# GD32G5x3 register map
File version: 1.0
CPU: CM33 r2p1, little endian, MPU, FPU, 4 interrupt priority bits
Registers are 32-bit, read-write, reset 0x0 unless marked. A register's access mark holds for its fields unless they carry their own. Offsets are from the block's base; [hi:lo] are bit positions; {n}, {i} and the like mark numbered series.

## HRTIMER_SLAVE_TIMER2
Base 0x40015980
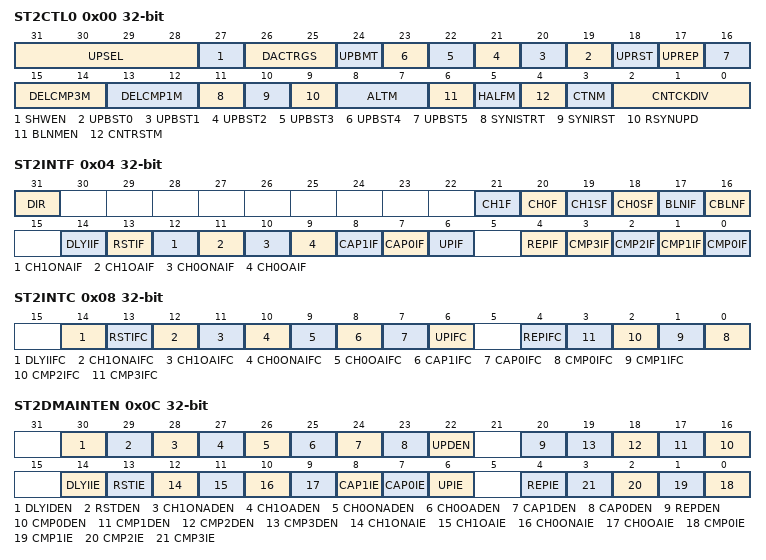
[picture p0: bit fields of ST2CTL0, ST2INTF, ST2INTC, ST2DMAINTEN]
0x00 ST2CTL0 — HRTIMER Slave_TIMER2 control register 0
  [31:28] UPSEL — Update event selection
  [27] SHWEN — Shadow registers enable
  [26:25] DACTRGS — Trigger source to DAC
  [24] UPBMT — Update by Master_TIMER update event
  [n+19] UPBST{n} (n=0..4) — Update by Slave_TIMER{n} update event
  [18] UPRST — Update event generated by reset event
  [17] UPREP — Update event generated by repetition event
  [16] UPBST5 — Update by Slave_TIMER5 update event
  [15:14] DELCMP3M — Compare 3 delayed mode
  [13:12] DELCMP1M — Compare 1 delayed mode
  [11] SYNISTRT — Synchronous input start timer
  [10] SYNIRST — Synchronous input reset timer
  [9] RSYNUPD — Re-synchronized update
  [8:7] ALTM — Alternate mode
  [6] BLNMEN — Balanced mode enable
  [5] HALFM — Half mode
  [4] CNTRSTM — Counter reset mode
  [3] CTNM — Continuous mode
  [2:0] CNTCKDIV — Counter clock division
0x04 ST2INTF ro — HRTIMER Slave_TIMER2 interrupt flag register
  [31] DIR — Direction
  [21] CH1F — Channel 1 output flag
  [20] CH0F — Channel 0 output flag
  [19] CH1SF — Channel 1 output state flag
  [18] CH0SF — Channel 0 output state flag
  [17] BLNIF — Balanced IDLE flag
  [16] CBLNF — Current balanced flag
  [14] DLYIIF — Delayed IDLE mode entry interrupt flag
  [13] RSTIF — Counter reset interrupt flag
  [12] CH1ONAIF — Channel 1 output inactive interrupt flag
  [11] CH1OAIF — Channel 1 output active interrupt flag
  [10] CH0ONAIF — Channel 0 output inactive interrupt flag
  [9] CH0OAIF — Channel 0 output active interrupt flag
  [8] CAP1IF — Capture 1 interrupt flag
  [7] CAP0IF — Capture 0 interrupt flag
  [6] UPIF — Update interrupt flag
  [4] REPIF — Repetition interrupt flag
  [n] CMP{n}IF (n=0..3) — Compare {n} interrupt flag
0x08 ST2INTC wo — HRTIMER Slave_TIMER2 interrupt flag clear register
  [14] DLYIIFC — Clear delayed IDLE mode entry interrupt flag
  [13] RSTIFC — Clear counter reset interrupt flag
  [12] CH1ONAIFC — Clear channel 1 output inactive interrupt flag
  [11] CH1OAIFC — Clear channel 1 output active interrupt flag
  [10] CH0ONAIFC — Clear channel 0 output inactive interrupt flag
  [9] CH0OAIFC — Clear channel 0 output active interrupt flag
  [8] CAP1IFC — Clear capture 1 interrupt flag
  [7] CAP0IFC — Clear capture 0 interrupt flag
  [6] UPIFC — Clear update interrupt flag
  [4] REPIFC — Clear repetition interrupt flag
  [n] CMP{n}IFC (n=0..3) — Clear compare {n} interrupt flag
0x0C ST2DMAINTEN — HRTIMER Slave_TIMER2 DMA and interrupt enable register
  [30] DLYIDEN — Delayed IDLE mode entry DMA request enable
  [29] RSTDEN — Counter reset DMA request enable
  [28] CH1ONADEN — Channel 1 output inactive DMA request enable
  [27] CH1OADEN — Channel 1 output active DMA request enable
  [26] CH0ONADEN — Channel 0 output inactive DMA request enable
  [25] CH0OADEN — Channel 0 output active DMA request enable
  [24] CAP1DEN — Capture 1 DMA request enable
  [23] CAP0DEN — Capture 0 DMA request enable
  [22] UPDEN — Update DMA request enable
  [20] REPDEN — Repetition DMA request enable
  [n+16] CMP{n}DEN (n=0..3) — Compare {n} DMA request enable
  [14] DLYIIE — Delayed IDLE mode entry interrupt enable
  [13] RSTIE — Counter reset interrupt enable
  [12] CH1ONAIE — Channel 1 output inactive interrupt enable
  [11] CH1OAIE — Channel 1 output active interrupt enable
  [10] CH0ONAIE — Channel 0 output inactive interrupt enable
  [9] CH0OAIE — Channel 0 output active interrupt enable
  [8] CAP1IE — Capture 1 interrupt enable
  [7] CAP0IE — Capture 0 interrupt enable
  [6] UPIE — Update interrupt enable
  [4] REPIE — Repetition interrupt enable
  [n] CMP{n}IE (n=0..3) — Compare {n} interrupt enable
0x10 ST2CNT — HRTIMER Slave_TIMER2 counter register
  [15:0] CNT — The current counter value
0x14 ST2CAR reset 0xFFDF — HRTIMER Slave_TIMER2 counter auto reload register
  [15:0] CARL — Counter auto reload value
0x18 ST2CREP — HRTIMER Slave_TIMER2 counter repetition register
  [7:0] CREP — Counter repetition value
0x1C ST2CMP0V — HRTIMER Slave_TIMER2 compare 0 value register
  [15:0] CMP0VAL — Compare 0 value
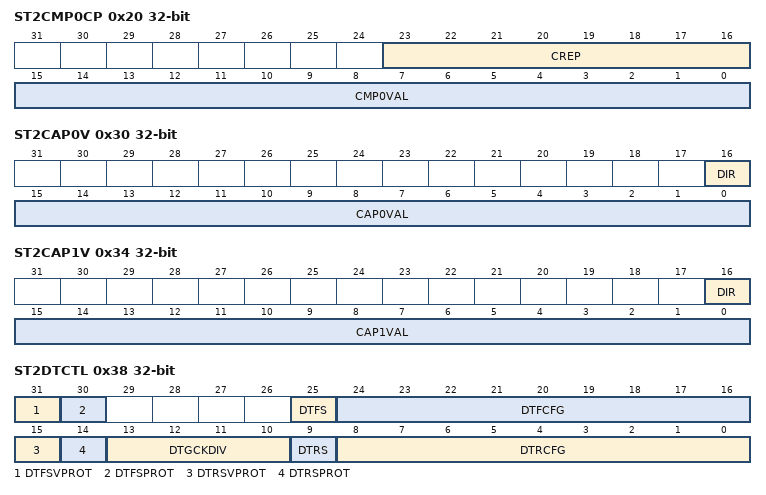
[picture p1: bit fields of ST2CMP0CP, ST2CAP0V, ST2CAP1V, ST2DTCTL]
0x20 ST2CMP0CP — HRTIMER Slave_TIMER2 compare 0 composite register
  [23:16] CREP — Counter repetition value
  [15:0] CMP0VAL — Compare 0 value
{0x20+4i} ST2CMP{i}V (i=1..3) — HRTIMER Slave_TIMER2 compare {i} value register
  [15:0] CMP{i}VAL — Compare {i} value
0x30 ST2CAP0V ro — HRTIMER Slave_TIMER2 capture 0 value register
  [16] DIR — Slave_timer 0 capture 1 direction status
  [15:0] CAP0VAL — Capture 0 value
0x34 ST2CAP1V ro — HRTIMER Slave_TIMER2 capture 1 value register
  [16] DIR — Slave_Timer 0 capture 1 direction status
  [15:0] CAP1VAL — Capture 1 value
0x38 ST2DTCTL — HRTIMER Slave_TIMER2 dead-time control register
  [31] DTFSVPROT — Dead-time falling edge protection for value and sign
  [30] DTFSPROT — Dead-time falling edge protection for sign
  [25] DTFS — The sign of falling edge dead-time value
  [24:16] DTFCFG — Falling edge dead-time value
  [15] DTRSVPROT — Dead-time rising edge protection for value and sign
  [14] DTRSPROT — Dead-time rising edge protection for sign
  [13:10] DTGCKDIV — Dead time clock division
  [9] DTRS — The sign of rising edge dead-time value
  [8:0] DTRCFG — Rising edge dead-time value
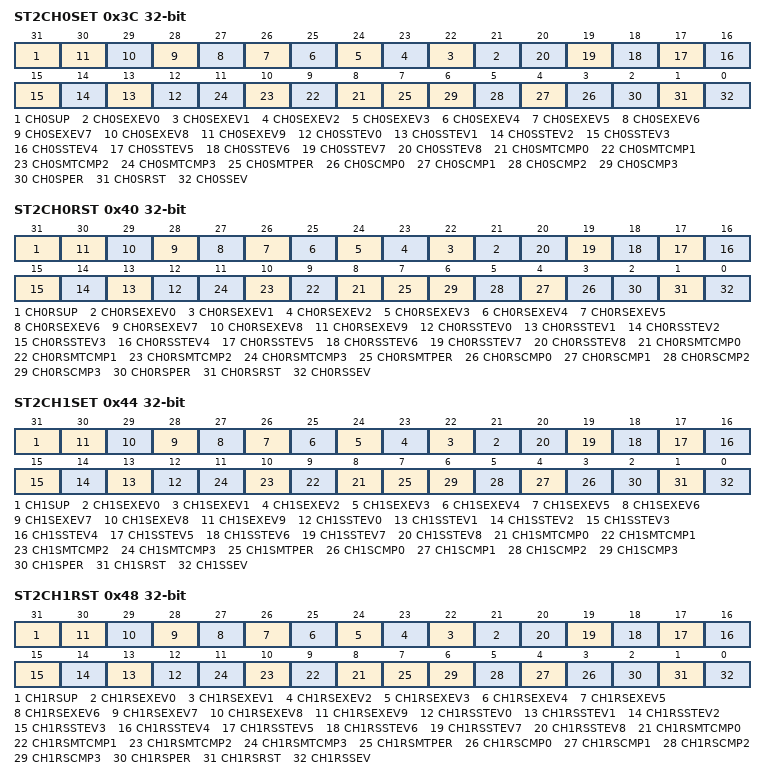
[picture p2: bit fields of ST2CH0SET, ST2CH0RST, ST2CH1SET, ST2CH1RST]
0x3C ST2CH0SET — HRTIMER Slave_TIMER2 channel 0 set request register
  [31] CH0SUP — Update event generates channel 0 set request
  [n+21] CH0SEXEV{n} (n=0..9) — External event {n} generates channel 0 set request
  [n+12] CH0SSTEV{n} (n=0..8) — interconnection event {n} generates channel 0 set request
  [n+8] CH0SMTCMP{n} (n=0..3) — Master_TIMER compare {n} event generates channel 0 set request
  [7] CH0SMTPER — Master_TIMER period event generates channel 0 set request
  [n+3] CH0SCMP{n} (n=0..3) — compare {n} event generates channel 0 set request
  [2] CH0SPER — period event generates channel 0 set request
  [1] CH0SRST — reset event generates channel 0 set request
  [0] CH0SSEV — Software event generates channel 0 set request
0x40 ST2CH0RST — HRTIMER Slave_TIMER2 channel 0 reset request register
  [31] CH0RSUP — Update event generates channel 0 reset request
  [n+21] CH0RSEXEV{n} (n=0..9) — External event {n} generates channel 0 reset request
  [n+12] CH0RSSTEV{n} (n=0..8) — interconnection event {n} generates channel 0 reset request
  [n+8] CH0RSMTCMP{n} (n=0..3) — Master_TIMER compare {n} event generates channel 0 reset request
  [7] CH0RSMTPER — Master_TIMER period event generates channel 0 reset request
  [n+3] CH0RSCMP{n} (n=0..3) — compare {n} event generates channel 0 reset request
  [2] CH0RSPER — period event generates channel 0 reset request
  [1] CH0RSRST — reset event generates channel 0 reset request
  [0] CH0RSSEV — Software event generates channel 0 reset request
0x44 ST2CH1SET — HRTIMER Slave_TIMER2 channel 1 set request register
  [31] CH1SUP — Update event generates channel 1 set request
  [n+21] CH1SEXEV{n} (n=0..9) — External event {n} generates channel 1 set request
  [n+12] CH1SSTEV{n} (n=0..8) — interconnection event {n} generates channel 1 set request
  [n+8] CH1SMTCMP{n} (n=0..3) — Master_TIMER compare {n} event generates channel 1 set request
  [7] CH1SMTPER — Master_TIMER period event generates channel 1 set request
  [n+3] CH1SCMP{n} (n=0..3) — compare {n} event generates channel 1 set request
  [2] CH1SPER — period event generates channel 1 set request
  [1] CH1SRST — reset event generates channel 1 set request
  [0] CH1SSEV — Software event generates channel 1 set request
0x48 ST2CH1RST — HRTIMER Slave_TIMER2 channel 1 reset request register
  [31] CH1RSUP — Update event generates channel 1 reset request
  [n+21] CH1RSEXEV{n} (n=0..9) — External event {n} generates channel 1 reset request
  [n+12] CH1RSSTEV{n} (n=0..8) — interconnection event {n} generates channel 1 reset request
  [n+8] CH1RSMTCMP{n} (n=0..3) — Master_TIMER compare {n} event generates channel 1 reset request
  [7] CH1RSMTPER — Master_TIMER period event generates channel 1 reset request
  [n+3] CH1RSCMP{n} (n=0..3) — compare {n} event generates channel 1 reset request
  [2] CH1RSPER — period event generates channel 1 reset request
  [1] CH1RSRST — reset event generates channel 1 reset request
  [0] CH1RSSEV — Software event generates channel 1 reset request
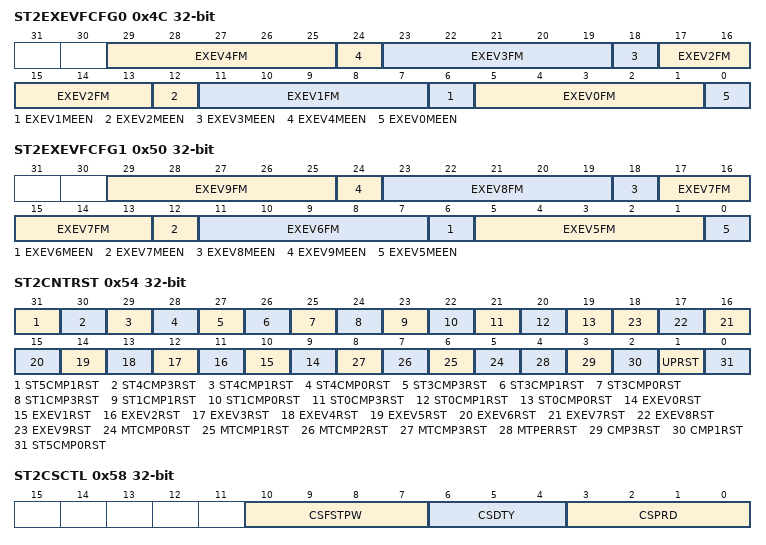
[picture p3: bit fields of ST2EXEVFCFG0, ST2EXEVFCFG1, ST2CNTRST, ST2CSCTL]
0x4C ST2EXEVFCFG0 — HRTIMER Slave_TIMER2 external event filter configuration register 0
  [6n+5:6n+1] EXEV{n}FM (n=0..4) — External event {n} filter mode
  [6n] EXEV{n}MEEN (n=1..4) — External event {n} memorized enable
  [0] EXEV0MEEN — External event 0 memory
0x50 ST2EXEVFCFG1 — HRTIMER Slave_TIMER2 external event filter configuration register 1
  [6n-25:6n-29] EXEV{n}FM (n=5..9) — External event {n} filter mode
  [6n-30] EXEV{n}MEEN (n=6..9) — External event {n} memorized enable
  [0] EXEV5MEEN — External event 0 memorized enable
0x54 ST2CNTRST — HRTIMER Slave_TIMER2 counter reset register
  [31] ST5CMP1RST — Slave_TIMER5 compare 1 event resets counter
  [30] ST4CMP3RST — Slave_TIMER4 compare 3 event resets counter
  [29] ST4CMP1RST — Slave_TIMER4 compare 1 event resets counter
  [28] ST4CMP0RST — Slave_TIMER4 compare 0 event resets counter
  [27] ST3CMP3RST — Slave_TIMER3 compare 3 event resets counter
  [26] ST3CMP1RST — Slave_TIMER3 compare 1 event resets counter
  [25] ST3CMP0RST — Slave_TIMER3 compare 0 event resets counter
  [24] ST1CMP3RST — Slave_TIMER1 compare 3 event resets counter
  [23] ST1CMP1RST — Slave_TIMER1 compare 1 event resets counter
  [22] ST1CMP0RST — Slave_TIMER1 compare 0 event resets counter
  [21] ST0CMP3RST — Slave_TIMER0 compare 3 event resets counter
  [20] ST0CMP1RST — Slave_TIMER0 compare 1 event resets counter
  [19] ST0CMP0RST — Slave_TIMER0 compare 0 event resets counter
  [n+9] EXEV{n}RST (n=0..9) — External event {n} resets counter
  [n+5] MTCMP{n}RST (n=0..3) — Master_TIMER compare {n} event resets counter
  [4] MTPERRST — Master_TIMER period event resets counter
  [3] CMP3RST — Slave_TIMER2 compare 3 event resets counter
  [2] CMP1RST — Slave_TIMER2 compare 1 event resets counter
  [1] UPRST — Slave_TIMER2 update event resets counter
  [0] ST5CMP0RST — Slave_TIMER5 compare 0 event resets counter
0x58 ST2CSCTL — HRTIMER Slave_TIMER2 carrier-signal control register
  [10:7] CSFSTPW — First carrier-signal pulse width
  [6:4] CSDTY — Carrier signal duty cycle
  [3:0] CSPRD — Carrier signal period
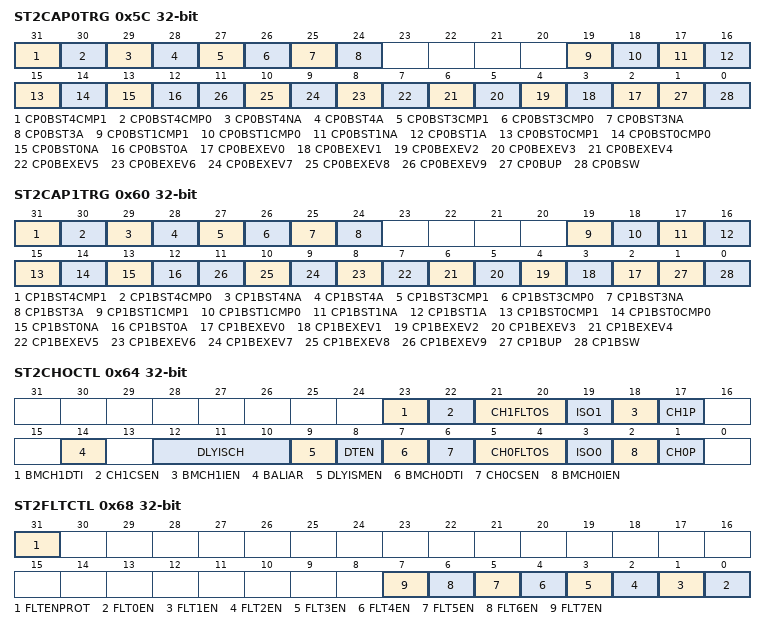
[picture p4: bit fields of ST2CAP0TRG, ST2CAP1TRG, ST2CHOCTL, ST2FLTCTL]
0x5C ST2CAP0TRG — HRTIMER Slave_TIMER2 capture 0 trigger register
  [31] CP0BST4CMP1 — Capture 0 triggered by compare 1 event of Slave_TIMER4
  [30] CP0BST4CMP0 — Capture 0 triggered by compare 0 event of Slave_TIMER4
  [29] CP0BST4NA — Capture 0 triggered by ST4CH0_O output active to inactive transition
  [28] CP0BST4A — Capture 0 triggered by ST4CH0_O output inactive to active transition
  [27] CP0BST3CMP1 — Capture 0 triggered by compare 1 event of Slave_TIMER3
  [26] CP0BST3CMP0 — Capture 0 triggered by compare 0 event of Slave_TIMER3
  [25] CP0BST3NA — Capture 0 triggered by ST3CH0_O output active to inactive transition
  [24] CP0BST3A — Capture 0 triggered by ST3CH0_O output inactive to active transition
  [19] CP0BST1CMP1 — Capture 0 triggered by compare 1 event of Slave_TIMER1
  [18] CP0BST1CMP0 — Capture 0 triggered by compare 0 event of Slave_TIMER1
  [17] CP0BST1NA — Capture 0 triggered by ST1CH0_O output active to inactive transition
  [16] CP0BST1A — Capture 0 triggered by ST1CH0_O output inactive to active transition
  [15] CP0BST0CMP1 — Capture 0 triggered by compare 1 event of Slave_TIMER0
  [14] CP0BST0CMP0 — Capture 0 triggered by compare 0 event of Slave_TIMER0
  [13] CP0BST0NA — Capture 0 triggered by ST0CH0_O output active to inactive transition
  [12] CP0BST0A — Capture 0 triggered by ST0CH0_O output inactive to active transition
  [n+2] CP0BEXEV{n} (n=0..9) — Capture 0 triggered by external event {n}
  [1] CP0BUP — Capture 0 triggered by update event
  [0] CP0BSW — Capture 0 triggered by software
0x60 ST2CAP1TRG — HRTIMER Slave_TIMER2 capture 1 trigger register
  [31] CP1BST4CMP1 — Capture 1 triggered by compare 1 event of Slave_TIMER4
  [30] CP1BST4CMP0 — Capture 1 triggered by compare 0 event of Slave_TIMER4
  [29] CP1BST4NA — Capture 1 triggered by ST4CH0_O output active to inactive transition
  [28] CP1BST4A — Capture 1 triggered by ST4CH0_O output inactive to active transition
  [27] CP1BST3CMP1 — Capture 1 triggered by compare 1 event of Slave_TIMER3
  [26] CP1BST3CMP0 — Capture 1 triggered by compare 0 event of Slave_TIMER3
  [25] CP1BST3NA — Capture 1 triggered by ST3CH0_O output active to inactive transition
  [24] CP1BST3A — Capture 1 triggered by ST3CH0_O output inactive to active transition
  [19] CP1BST1CMP1 — Capture 1 triggered by compare 1 event of Slave_TIMER1
  [18] CP1BST1CMP0 — Capture 1 triggered by compare 0 event of Slave_TIMER1
  [17] CP1BST1NA — Capture 1 triggered by ST1CH0_O output active to inactive transition
  [16] CP1BST1A — Capture 1 triggered by ST1CH0_O output inactive to active transition
  [15] CP1BST0CMP1 — Capture 1 triggered by compare 1 event of Slave_TIMER0
  [14] CP1BST0CMP0 — Capture 1 triggered by compare 0 event of Slave_TIMER0
  [13] CP1BST0NA — Capture 1 triggered by ST0CH0_O output active to inactive transition
  [12] CP1BST0A — Capture 1 triggered by ST0CH0_O output inactive to active transition
  [n+2] CP1BEXEV{n} (n=0..9) — Capture 1 triggered by external event {n}
  [1] CP1BUP — Capture 1 triggered by update event
  [0] CP1BSW — Capture 1 triggered by software
0x64 ST2CHOCTL — HRTIMER Slave_TIMER2 channel output control register
  [23] BMCH1DTI — Channel 1 dead-time insert in bunch mode
  [22] CH1CSEN — Channel 1 carrier-signal mode enable
  [21:20] CH1FLTOS — Channel 1 Fault output state
  [19] ISO1 — channel 1 output idle state
  [18] BMCH1IEN — Channel 1 IDLE state enable in bunch mode
  [17] CH1P — Channel 1 output polarity
  [14] BALIAR — Balanced Idle Automatic Resumption
  [12:10] DLYISCH — Delayed IDLE source and channel
  [9] DLYISMEN — Delayed IDLE state mode enable
  [8] DTEN — Dead time enable
  [7] BMCH0DTI — Channel 0 dead-time insert in bunch mode
  [6] CH0CSEN — Channel 0 carrier-signal mode enable
  [5:4] CH0FLTOS — Channel 0 Fault output state
  [3] ISO0 — Channel 0 output idle state
  [2] BMCH0IEN — Channel 0 IDLE state enable in bunch mode
  [1] CH0P — Channel 0 output polarity
0x68 ST2FLTCTL — HRTIMER Slave_TIMER2 fault control register
  [31] FLTENPROT — Protect fault enable
  [n] FLT{n}EN (n=0..7) — Fault {n} enable
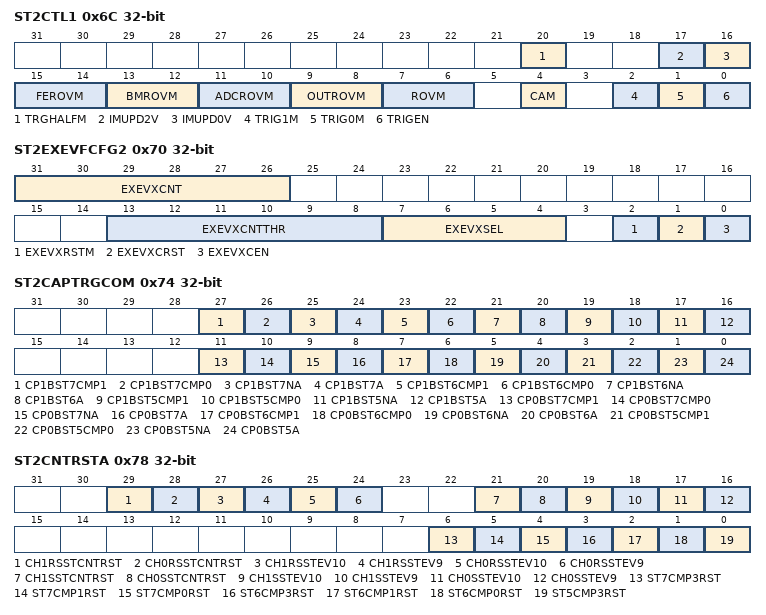
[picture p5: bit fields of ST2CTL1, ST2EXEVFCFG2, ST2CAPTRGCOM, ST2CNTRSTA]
0x6C ST2CTL1 — HRTIMER Slave_TIMER2 control register 1
  [20] TRGHALFM — Triggered-half mode
  [17] IMUPD2V — Immediately update compare 2 value PWM mode
  [16] IMUPD0V — Immediately update compare 0 value PWM mode
  [15:14] FEROVM — Fault and event roll-over mode
  [13:12] BMROVM — Bunch mode roll-over mode
  [11:10] ADCROVM — ADC roll-over mode
  [9:8] OUTROVM — Output roll-over mode
  [7:6] ROVM — Roll-over mode
  [4] CAM — Center-aligned counting mode
  [2] TRIG1M — This bit defines when TRIG1M is generated
  [1] TRIG0M — This bit defines when TRIG0M is generated
  [0] TRIGEN — Two trigger enable
0x70 ST2EXEVFCFG2 — HRTIMER Slave_TIMER2 external event filter configuration register 2
  [31:26] EXEVXCNT — External event X counter value
  [13:8] EXEVXCNTTHR — External event X counter threshold
  [7:4] EXEVXSEL — External event X selection This bit determines the source of external event X
  [2] EXEVXRSTM — External event X reset mode
  [1] EXEVXCRST — External event X counter reset
  [0] EXEVXCEN — External event X counter enable
0x74 ST2CAPTRGCOM — HRTIMER Slave_TIMER2 capture trigger combination register
  [27] CP1BST7CMP1 — Capture 1 triggered by compare 1 event of Slave_TIMER7
  [26] CP1BST7CMP0 — Capture 1 triggered by compare 0 event of Slave_TIMER7
  [25] CP1BST7NA — Capture 1 triggered by ST0CH0_O output active to inactive transition
  [24] CP1BST7A — Capture 1 triggered by ST0CH0_O output inactive to active transition
  [23] CP1BST6CMP1 — Capture 1 triggered by compare 1 event of Slave_TIMER6
  [22] CP1BST6CMP0 — Capture 1 triggered by compare 0 event of Slave_TIMER6
  [21] CP1BST6NA — Capture 1 triggered by ST0CH0_O output active to inactive transition
  [20] CP1BST6A — Capture 1 triggered by ST0CH0_O output inactive to active transition
  [19] CP1BST5CMP1 — Capture 1 triggered by compare 1 event of Slave_TIMER5
  [18] CP1BST5CMP0 — Capture 1 triggered by compare 0 event of Slave_TIMER5
  [17] CP1BST5NA — Capture 1 triggered by ST0CH0_O output active to inactive transition
  [16] CP1BST5A — Capture 1 triggered by ST0CH0_O output inactive to active transition
  [11] CP0BST7CMP1 — Capture 0 triggered by compare 1 event of Slave_TIMER7
  [10] CP0BST7CMP0 — Capture 0 triggered by compare 0 event of Slave_TIMER7
  [9] CP0BST7NA — Capture 0 triggered by ST0CH0_O output active to inactive transition
  [8] CP0BST7A — Capture 0 triggered by ST0CH0_O output inactive to active transition
  [7] CP0BST6CMP1 — Capture 0 triggered by compare 1 event of Slave_TIMER6
  [6] CP0BST6CMP0 — Capture 0 triggered by compare 0 event of Slave_TIMER6
  [5] CP0BST6NA — Capture 0 triggered by ST0CH0_O output active to inactive transition
  [4] CP0BST6A — Capture 0 triggered by ST0CH0_O output inactive to active transition
  [3] CP0BST5CMP1 — Capture 0 triggered by compare 1 event of Slave_TIMER5
  [2] CP0BST5CMP0 — Capture 0 triggered by compare 0 event of Slave_TIMER5
  [1] CP0BST5NA — Capture 0 triggered by ST0CH0_O output active to inactive transition
  [0] CP0BST5A — Capture 0 triggered by ST0CH0_O output inactive to active transition
0x78 ST2CNTRSTA — HRTIMER Slave_TIMER2 counter reset and channel 0/1 set/reset request add register
  [29] CH1RSSTCNTRST — Slave_TIMER2 counter reset generates channel 1 reset request
  [28] CH0RSSTCNTRST — Slave_TIMER2 counter reset generates channel 0 reset request
  [27] CH1RSSTEV10 — Slave_TIMER2 interconnection event 10 generates channel 1 reset request
  [26] CH1RSSTEV9 — Slave_TIMER2 interconnection event 9 generates channel 1 reset request
  [25] CH0RSSTEV10 — Slave_TIMER2 interconnection event 10 generates channel 0 reset request
  [24] CH0RSSTEV9 — Slave_TIMER2 interconnection event 9 generates channel 0 reset request
  [21] CH1SSTCNTRST — Slave_TIMER2 counter reset generates channel 1 reset request
  [20] CH0SSTCNTRST — Slave_TIMER2 counter reset generates channel 0 reset request
  [19] CH1SSTEV10 — Slave_TIMER2 interconnection event 10 generates channel 1 reset request
  [18] CH1SSTEV9 — Slave_TIMER2 interconnection event 9 generates channel 1 reset request
  [17] CH0SSTEV10 — Slave_TIMER2 interconnection event 10 generates channel 0 set request
  [16] CH0SSTEV9 — Slave_TIMER2 interconnection event 9 generates channel 1 set request
  [6] ST7CMP3RST — Slave_TIMER7 compare 3 event resets counter
  [5] ST7CMP1RST — Slave_TIMER7 compare 1 event resets counter
  [4] ST7CMP0RST — Slave_TIMER7 compare 0 event resets counter
  [3] ST6CMP3RST — Slave_TIMER6 compare 3 event resets counter
  [2] ST6CMP1RST — Slave_TIMER6 compare 1 event resets counter
  [1] ST6CMP0RST — Slave_TIMER6 compare 0 event resets counter
  [0] ST5CMP3RST — Slave_TIMER5 compare 3 event resets counter
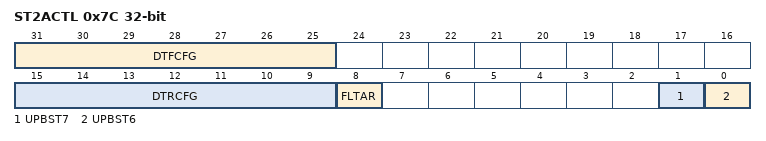
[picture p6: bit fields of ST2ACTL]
0x7C ST2ACTL — HRTIMER Slave_TIMER2 additional control register
  [31:25] DTFCFG — Falling edge dead-time value configure
  [15:9] DTRCFG — Rising edge dead-time value configure
  [8] FLTAR — Fault automatic resume
  [1] UPBST7 — Update by Slave_TIMER7 update event
  [0] UPBST6 — Update by Slave_TIMER6 update event
